# max32520 register map
Vendor: Maxim-Integrated; Series: ARMCM4; File version: 1.1
CPU: CM4 r2p1, little endian, MPU, FPU, 3 interrupt priority bits
Registers are 32-bit, read-write, reset 0x0 unless marked. A register's access mark holds for its fields unless they carry their own. Offsets are from the block's base; [hi:lo] are bit positions; {n}, {i} and the like mark numbered series; 'fields as' and 'values as' point back to an identical list.

## TRNG — Random Number Generator.
Base 0x4004D000
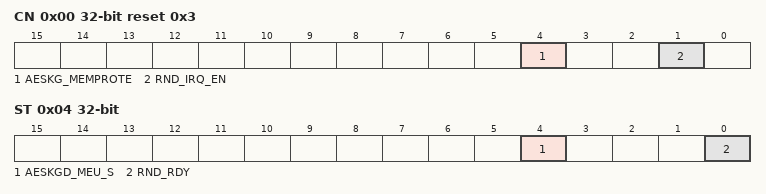
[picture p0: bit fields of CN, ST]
0x00 CN reset 0x3 — TRNG Control Register.
  [4] AESKG_MEMPROTE — AES Key Generate. When enabled, the key for securing NVSRAM is generated and transferred to the secure key register automatically without user visibility or intervention. This bit is cleared by hardware once the key has been transferred to the secure key register.
  [1] RND_IRQ_EN — To enable IRQ generation when a new 32-bit Random number is ready.
    0=disable; 1=enable
0x04 ST ro — Data. The content of this register is valid only when RNG_IS = 1. When TRNG is disabled, read returns 0x0000 0000.
  [4] AESKGD_MEU_S — Automatically AES transfer on going
  [0] RND_RDY — 32-bit random data is ready to read from TRNG_DATA register. Reading TRNG_DATA when RND_RDY=0 will return all 0's. IRQ is generated when RND_RDY=1 if TRNG_CN.RND_IRQ_EN=1.
    0=Busy (TRNG Busy); 1=Ready (32 bit random data is ready)
0x08 DATA ro — Data. The content of this register is valid only when RNG_IS = 1. When TRNG is disabled, read returns 0x0000 0000.
  [31:0] DATA — Data. The content of this register is valid only when RNG_IS =1. When TNRG is disabled, read returns 0x0000 0000.

## UART0 — UART
Base 0x40020000
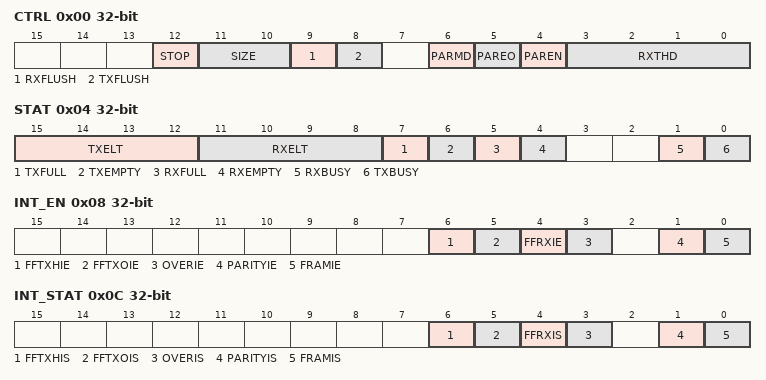
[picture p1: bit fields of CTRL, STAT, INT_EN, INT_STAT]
0x00 CTRL — Control Register.
  [12] STOP — Selects the number of stop bits that will be generated.
    0=1 stop bit; 1=1_5 (1.5 stop bits.)
  [11:10] SIZE — Selects UART character size.
    {v}={v+5} bits (v=0..3)
  [9] RXFLUSH — Flushes the RX FIFO buffer.
  [8] TXFLUSH — Flushes the TX FIFO buffer.
  [6] PARMD — Selects parity based on 1s or 0s count (when PARITY_EN=1).
    0=Parity calculation is based on number of 1s in frame; 1=Parity calculation is based on number of 0s in frame
  [5] PAREO — When PARITY_EN=1, selects odd or even parity.
    0=Even parity selected; 1=ODD (Odd parity selected.)
  [4] PAREN — Enable/disable Parity bit (9th character).
    0=dis (No Parity); 1=en (Parity enabled as 9th bit)
  [3:0] RXTHD — Receive Threshhold.
0x04 STAT ro — Status Register.
  [15:12] TXELT — Indicates the number of bytes currently in the TX FIFO.
  [11:8] RXELT — Indicates the number of bytes currently in the RX FIFO.
  [7] TXFULL — Read-only flag indicating the TX FIFO state.
  [6] TXEMPTY — Read-only flag indicating the TX FIFO state.
  [5] RXFULL — Read-only flag indicating the RX FIFO state.
  [4] RXEMPTY — Read-only flag indicating the RX FIFO state.
  [1] RXBUSY — Read-only flag indicating the UART receiver status.
  [0] TXBUSY — Read-only flag indicating the UART transmit status.
0x08 INT_EN — Interrupt Enable Register.
  [6] FFTXHIE — Enable for interrupt when TX FIFO reaches half the number of bytes allowed in the fifo or less.
  [5] FFTXOIE — Enable for interrupt when TX FIFO has only one byte remaining.
  [4] FFRXIE — Enable for interrupt when RX FIFO reaches the number of bytes configured by the RXTHD field.
  [3] OVERIE — Enable for RX FIFO OVerrun interrupt.
  [1] PARITYIE — Enable for RX Parity Error interrupt.
  [0] FRAMIE — Enable for RX Frame Error Interrupt.
0x0C INT_STAT write-1-clears — Interrupt Status Flags.
  [6] FFTXHIS — FLAG for interrupt when TX FIFO reaches half the number of bytes allowed in the fifo or less.
  [5] FFTXOIS — FLAG for interrupt when TX FIFO has only one byte remaining.
  [4] FFRXIS — FLAG for interrupt when RX FIFO reaches the number of bytes configured by the RXTHD field.
  [3] OVERIS — FLAG for RX FIFO Overrun interrupt.
  [1] PARITYIS — FLAG for RX Parity Error interrupt.
  [0] FRAMIS — FLAG for RX Frame Error Interrupt.
0x10 BAUD0 — Baud rate register. Integer portion.
  [11:0] IDIV — Integer portion of baud rate divisor value. IBAUD = InputClock / (factor * Baud Rate Frequency).
0x14 BAUD1 — Baud rate register. Decimal Setting.
  [6:0] DDIV — Decimal portion of baud rate divisor value. DIV = InputClock/(factor*Baud Rate Frequency). DDIV=(DIV-IDIV)*128.
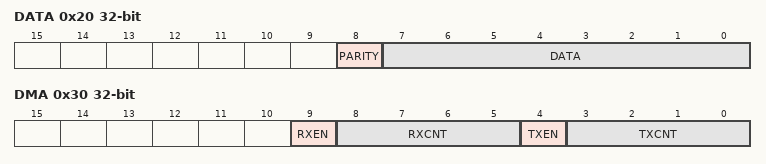
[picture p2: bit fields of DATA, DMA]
0x20 DATA — FIFO Data buffer.
  [8] PARITY — Parity error flag for next byte to be read from FIFO.
  [7:0] DATA — Load/unload location for TX and RX FIFO buffers.
0x30 DMA — DMA Configuration.
  [9] RXEN — RX DMA channel enable.
    0=dis (DMA is disabled); 1=en (DMA is enabled)
  [8:5] RXCNT — RX threshold for DMA transmission.
  [4] TXEN — TX DMA channel enable.
    0=dis (DMA is disabled); 1=en (DMA is enabled)
  [3:0] TXCNT — TX threshold for DMA transmission.

## WDT0 — Watchdog Timer 0
Base 0x40003000
Same registers: WDT1 0x40003400
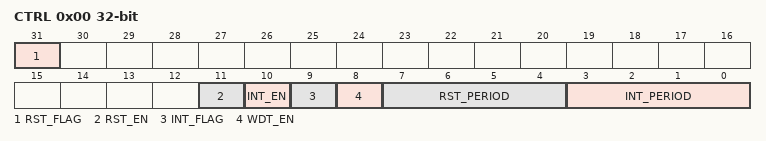
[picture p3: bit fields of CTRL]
0x00 CTRL (reset mask 0x7FFFF000) — Watchdog Timer Control Register.
  [31] RST_FLAG — Watchdog Timer Reset Flag.
    0=noEvent (The event has not occurred.); 1=occurred (The event has occurred.)
  [11] RST_EN — Watchdog Timer Reset Enable.
    0=dis (Disable.); 1=en (Enable.)
  [10] INT_EN — Watchdog Timer Interrupt Enable.
    0=dis (Disable.); 1=en (Enable.)
  [9] INT_FLAG write-1-clears — Watchdog Timer Interrupt Flag.
    0=inactive (No interrupt is pending.); 1=pending (An interrupt is pending.)
  [8] WDT_EN — Watchdog Timer Enable.
    0=dis (Disable.); 1=en (Enable.)
  [7:4] RST_PERIOD — Watchdog Reset Period. The watchdog timer will assert a reset, if enabled, if the CPU does not write the watchdog reset sequence to the WDT_RST register before the watchdog timer has counted this time period since the last timer reset.
    0=wdt2pow31 (2**31 clock cycles.); 1=wdt2pow30 (2**30 clock cycles.); 2=wdt2pow29 (2**29 clock cycles.); 3=wdt2pow28 (2**28 clock cycles.); 4=wdt2pow27 (2^27 clock cycles.); 5=wdt2pow26 (2**26 clock cycles.); 6=wdt2pow25 (2**25 clock cycles.); 7=wdt2pow24 (2**24 clock cycles.); 8=wdt2pow23 (2**23 clock cycles.); 9=wdt2pow22 (2**22 clock cycles.); 10=wdt2pow21 (2**21 clock cycles.); 11=wdt2pow20 (2**20 clock cycles.); 12=wdt2pow19 (2**19 clock cycles.); 13=wdt2pow18 (2**18 clock cycles.); 14=wdt2pow17 (2**17 clock cycles.); 15=wdt2pow16 (2**16 clock cycles.)
  [3:0] INT_PERIOD — Watchdog Interrupt Period. The watchdog timer will assert an interrupt, if enabled, if the CPU does not write the watchdog reset sequence to the WDT_RST register before the watchdog timer has counted this time period since the last timer reset.
    values as RST_PERIOD
0x04 RST wo — Watchdog Timer Reset Register.
  [7:0] WDT_RST — Writing the watchdog counter 'reset sequence' to this register resets the watchdog counter. If the watchdog count exceeds INT_PERIOD then a watchdog interrupt will occur, if enabled. If the watchdog count exceeds RST_PERIOD then a watchdog reset will occur, if enabled.
    165=seq0 (The first value to be written to reset the WDT.); 90=seq1 (The second value to be written to reset the WDT.)
